VERSION "synthetic -- generated by libs/dbc_parser/tests/gen_golden.py"

NS_ :

BS_:

BU_ : ECU

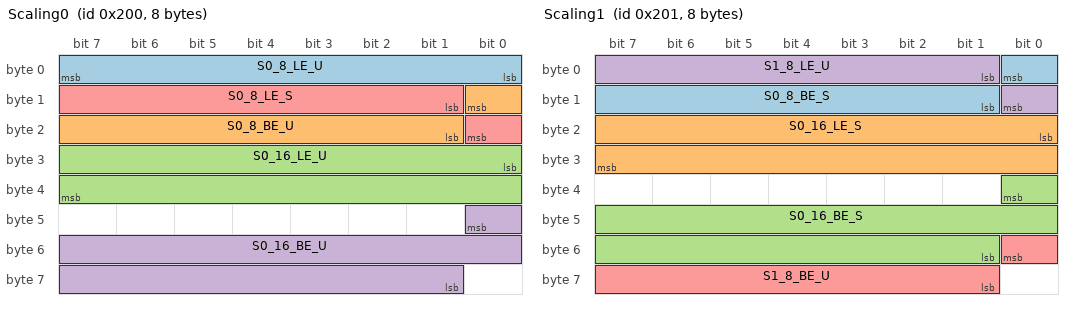
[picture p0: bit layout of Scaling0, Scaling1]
BO_ 512 Scaling0: 8 ECU
 SG_ S0_8_LE_U : 0|8@1+ (1,0) [0|255] "" ECU
 SG_ S0_8_BE_U : 8|8@0+ (1,0) [0|255] "" ECU
 SG_ S0_16_LE_U : 24|16@1+ (1,0) [0|65535] "" ECU
 SG_ S0_16_BE_U : 40|16@0+ (1,0) [0|65535] "" ECU
 SG_ S0_8_LE_S : 9|8@1- (1,0) [-128|127] "" ECU

BO_ 513 Scaling1: 8 ECU
 SG_ S0_8_BE_S : 0|8@0- (1,0) [-128|127] "" ECU
 SG_ S0_16_LE_S : 16|16@1- (1,0) [-32768|32767] "" ECU
 SG_ S0_16_BE_S : 32|16@0- (1,0) [-32768|32767] "" ECU
 SG_ S1_8_LE_U : 1|8@1+ (1,-40) [-40|215] "" ECU
 SG_ S1_8_BE_U : 48|8@0+ (1,-40) [-40|215] "" ECU

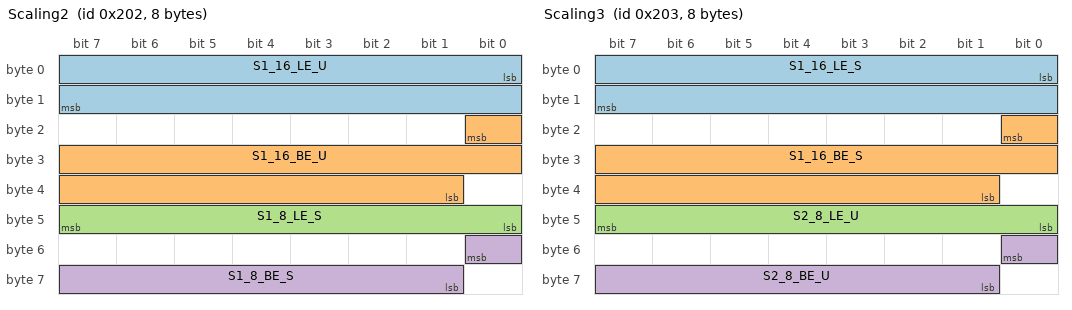
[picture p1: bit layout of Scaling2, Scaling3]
BO_ 514 Scaling2: 8 ECU
 SG_ S1_16_LE_U : 0|16@1+ (1,-40) [-40|65495] "" ECU
 SG_ S1_16_BE_U : 16|16@0+ (1,-40) [-40|65495] "" ECU
 SG_ S1_8_LE_S : 40|8@1- (1,-40) [-168|87] "" ECU
 SG_ S1_8_BE_S : 48|8@0- (1,-40) [-168|87] "" ECU

BO_ 515 Scaling3: 8 ECU
 SG_ S1_16_LE_S : 0|16@1- (1,-40) [-32808|32727] "" ECU
 SG_ S1_16_BE_S : 16|16@0- (1,-40) [-32808|32727] "" ECU
 SG_ S2_8_LE_U : 40|8@1+ (1,100) [100|355] "" ECU
 SG_ S2_8_BE_U : 48|8@0+ (1,100) [100|355] "" ECU

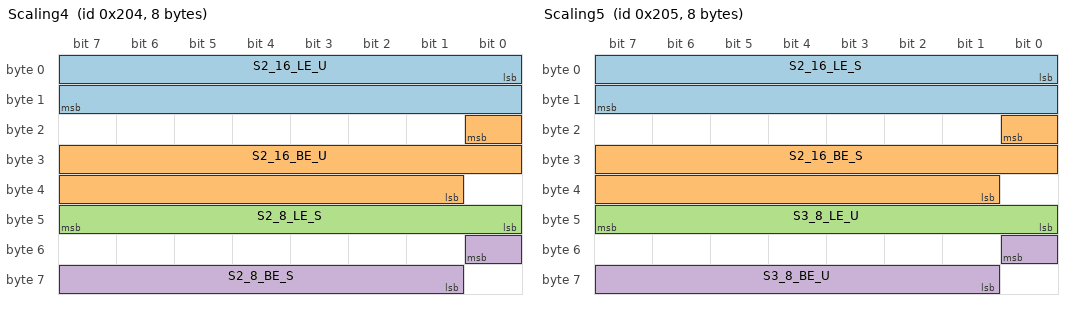
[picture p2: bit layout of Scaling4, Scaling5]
BO_ 516 Scaling4: 8 ECU
 SG_ S2_16_LE_U : 0|16@1+ (1,100) [100|65635] "" ECU
 SG_ S2_16_BE_U : 16|16@0+ (1,100) [100|65635] "" ECU
 SG_ S2_8_LE_S : 40|8@1- (1,100) [-28|227] "" ECU
 SG_ S2_8_BE_S : 48|8@0- (1,100) [-28|227] "" ECU

BO_ 517 Scaling5: 8 ECU
 SG_ S2_16_LE_S : 0|16@1- (1,100) [-32668|32867] "" ECU
 SG_ S2_16_BE_S : 16|16@0- (1,100) [-32668|32867] "" ECU
 SG_ S3_8_LE_U : 40|8@1+ (0.1,0) [0.0|25.5] "" ECU
 SG_ S3_8_BE_U : 48|8@0+ (0.1,0) [0.0|25.5] "" ECU

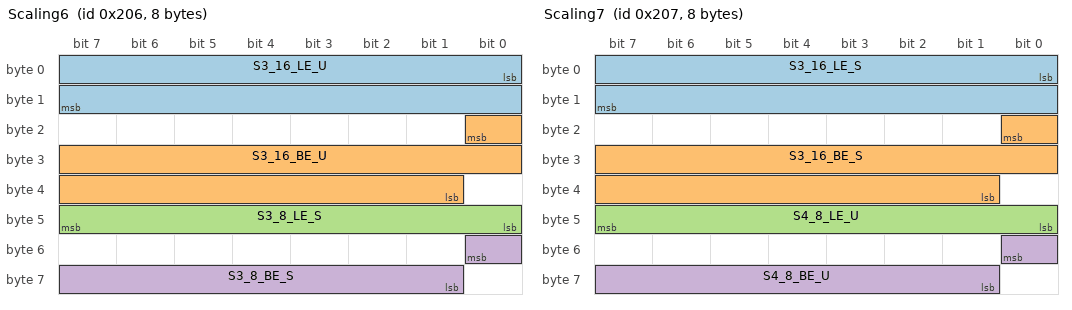
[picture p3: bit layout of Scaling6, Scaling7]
BO_ 518 Scaling6: 8 ECU
 SG_ S3_16_LE_U : 0|16@1+ (0.1,0) [0.0|6553.5] "" ECU
 SG_ S3_16_BE_U : 16|16@0+ (0.1,0) [0.0|6553.5] "" ECU
 SG_ S3_8_LE_S : 40|8@1- (0.1,0) [-12.8|12.700000000000001] "" ECU
 SG_ S3_8_BE_S : 48|8@0- (0.1,0) [-12.8|12.700000000000001] "" ECU

BO_ 519 Scaling7: 8 ECU
 SG_ S3_16_LE_S : 0|16@1- (0.1,0) [-3276.8|3276.7000000000003] "" ECU
 SG_ S3_16_BE_S : 16|16@0- (0.1,0) [-3276.8|3276.7000000000003] "" ECU
 SG_ S4_8_LE_U : 40|8@1+ (0.5,-273.15) [-273.15|-145.64999999999998] "" ECU
 SG_ S4_8_BE_U : 48|8@0+ (0.5,-273.15) [-273.15|-145.64999999999998] "" ECU

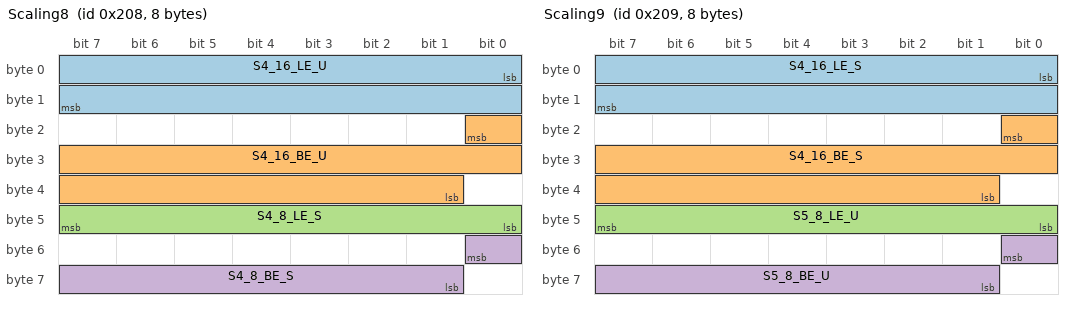
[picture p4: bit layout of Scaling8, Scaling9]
BO_ 520 Scaling8: 8 ECU
 SG_ S4_16_LE_U : 0|16@1+ (0.5,-273.15) [-273.15|32494.35] "" ECU
 SG_ S4_16_BE_U : 16|16@0+ (0.5,-273.15) [-273.15|32494.35] "" ECU
 SG_ S4_8_LE_S : 40|8@1- (0.5,-273.15) [-337.15|-209.64999999999998] "" ECU
 SG_ S4_8_BE_S : 48|8@0- (0.5,-273.15) [-337.15|-209.64999999999998] "" ECU

BO_ 521 Scaling9: 8 ECU
 SG_ S4_16_LE_S : 0|16@1- (0.5,-273.15) [-16657.15|16110.35] "" ECU
 SG_ S4_16_BE_S : 16|16@0- (0.5,-273.15) [-16657.15|16110.35] "" ECU
 SG_ S5_8_LE_U : 40|8@1+ (-1,0) [-255|0] "" ECU
 SG_ S5_8_BE_U : 48|8@0+ (-1,0) [-255|0] "" ECU

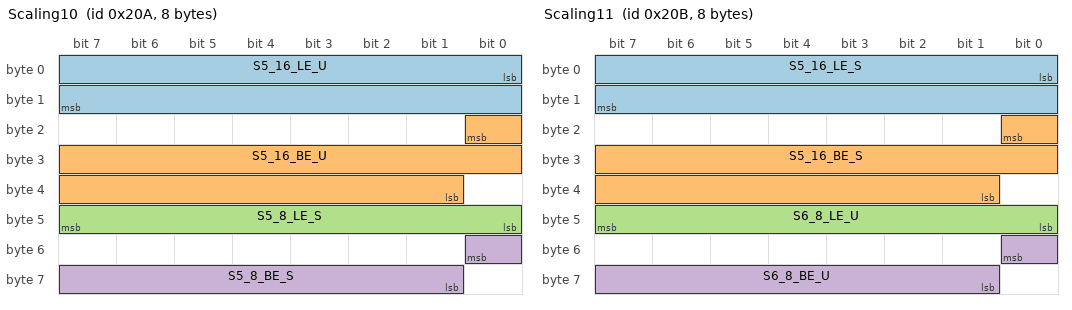
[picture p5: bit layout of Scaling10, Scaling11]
BO_ 522 Scaling10: 8 ECU
 SG_ S5_16_LE_U : 0|16@1+ (-1,0) [-65535|0] "" ECU
 SG_ S5_16_BE_U : 16|16@0+ (-1,0) [-65535|0] "" ECU
 SG_ S5_8_LE_S : 40|8@1- (-1,0) [-127|128] "" ECU
 SG_ S5_8_BE_S : 48|8@0- (-1,0) [-127|128] "" ECU

BO_ 523 Scaling11: 8 ECU
 SG_ S5_16_LE_S : 0|16@1- (-1,0) [-32767|32768] "" ECU
 SG_ S5_16_BE_S : 16|16@0- (-1,0) [-32767|32768] "" ECU
 SG_ S6_8_LE_U : 40|8@1+ (-0.25,10) [-53.75|10.0] "" ECU
 SG_ S6_8_BE_U : 48|8@0+ (-0.25,10) [-53.75|10.0] "" ECU

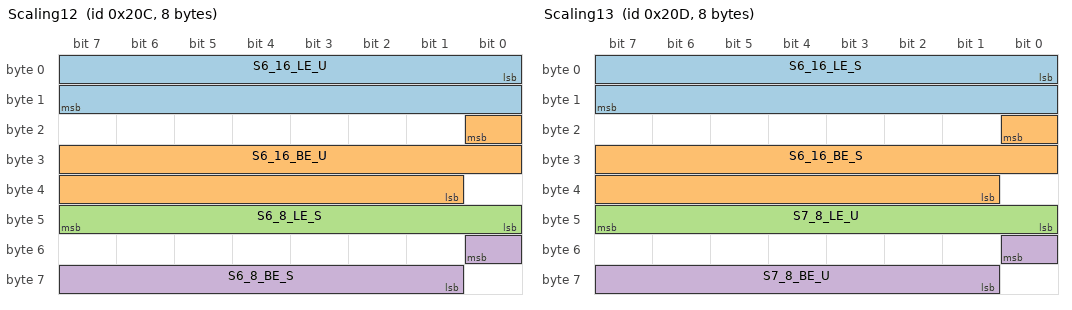
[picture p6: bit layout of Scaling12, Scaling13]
BO_ 524 Scaling12: 8 ECU
 SG_ S6_16_LE_U : 0|16@1+ (-0.25,10) [-16373.75|10.0] "" ECU
 SG_ S6_16_BE_U : 16|16@0+ (-0.25,10) [-16373.75|10.0] "" ECU
 SG_ S6_8_LE_S : 40|8@1- (-0.25,10) [-21.75|42.0] "" ECU
 SG_ S6_8_BE_S : 48|8@0- (-0.25,10) [-21.75|42.0] "" ECU

BO_ 525 Scaling13: 8 ECU
 SG_ S6_16_LE_S : 0|16@1- (-0.25,10) [-8181.75|8202.0] "" ECU
 SG_ S6_16_BE_S : 16|16@0- (-0.25,10) [-8181.75|8202.0] "" ECU
 SG_ S7_8_LE_U : 40|8@1+ (2,0) [0|510] "" ECU
 SG_ S7_8_BE_U : 48|8@0+ (2,0) [0|510] "" ECU

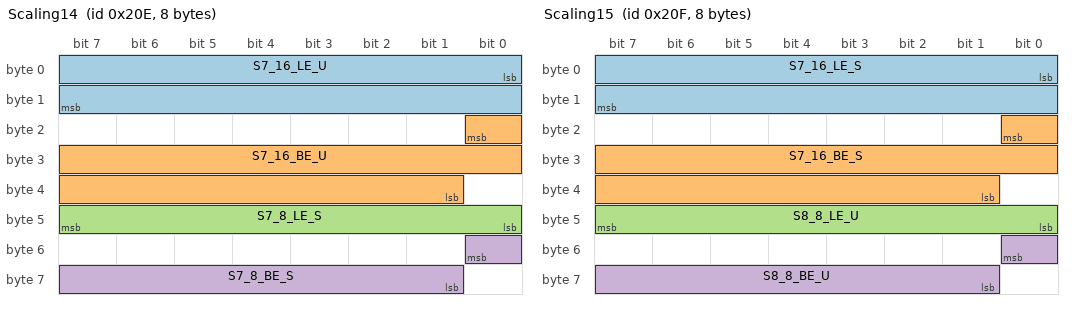
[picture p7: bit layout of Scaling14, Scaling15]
BO_ 526 Scaling14: 8 ECU
 SG_ S7_16_LE_U : 0|16@1+ (2,0) [0|131070] "" ECU
 SG_ S7_16_BE_U : 16|16@0+ (2,0) [0|131070] "" ECU
 SG_ S7_8_LE_S : 40|8@1- (2,0) [-256|254] "" ECU
 SG_ S7_8_BE_S : 48|8@0- (2,0) [-256|254] "" ECU

BO_ 527 Scaling15: 8 ECU
 SG_ S7_16_LE_S : 0|16@1- (2,0) [-65536|65534] "" ECU
 SG_ S7_16_BE_S : 16|16@0- (2,0) [-65536|65534] "" ECU
 SG_ S8_8_LE_U : 40|8@1+ (0.001,0) [0.0|0.255] "" ECU
 SG_ S8_8_BE_U : 48|8@0+ (0.001,0) [0.0|0.255] "" ECU

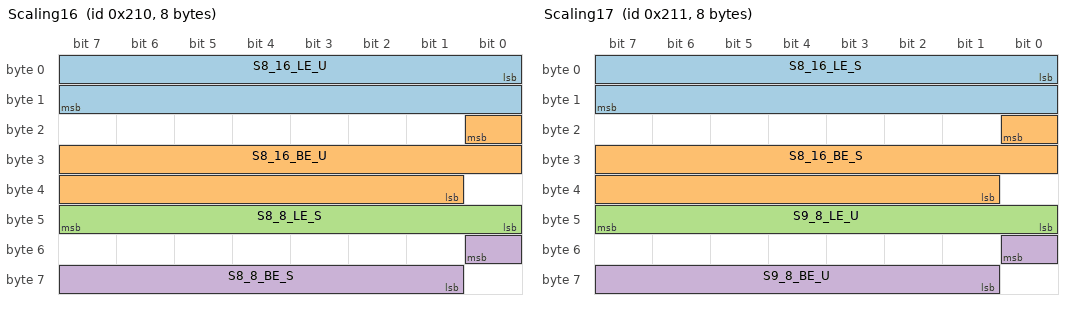
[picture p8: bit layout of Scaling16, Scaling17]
BO_ 528 Scaling16: 8 ECU
 SG_ S8_16_LE_U : 0|16@1+ (0.001,0) [0.0|65.535] "" ECU
 SG_ S8_16_BE_U : 16|16@0+ (0.001,0) [0.0|65.535] "" ECU
 SG_ S8_8_LE_S : 40|8@1- (0.001,0) [-0.128|0.127] "" ECU
 SG_ S8_8_BE_S : 48|8@0- (0.001,0) [-0.128|0.127] "" ECU

BO_ 529 Scaling17: 8 ECU
 SG_ S8_16_LE_S : 0|16@1- (0.001,0) [-32.768|32.767] "" ECU
 SG_ S8_16_BE_S : 16|16@0- (0.001,0) [-32.768|32.767] "" ECU
 SG_ S9_8_LE_U : 40|8@1+ (1000,0) [0|255000] "" ECU
 SG_ S9_8_BE_U : 48|8@0+ (1000,0) [0|255000] "" ECU

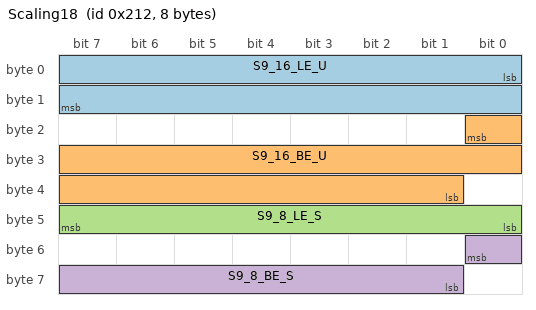
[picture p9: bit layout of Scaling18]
BO_ 530 Scaling18: 8 ECU
 SG_ S9_16_LE_U : 0|16@1+ (1000,0) [0|65535000] "" ECU
 SG_ S9_16_BE_U : 16|16@0+ (1000,0) [0|65535000] "" ECU
 SG_ S9_8_LE_S : 40|8@1- (1000,0) [-128000|127000] "" ECU
 SG_ S9_8_BE_S : 48|8@0- (1000,0) [-128000|127000] "" ECU

BO_ 531 Scaling19: 8 ECU
 SG_ S9_16_LE_S : 0|16@1- (1000,0) [-32768000|32767000] "" ECU
 SG_ S9_16_BE_S : 16|16@0- (1000,0) [-32768000|32767000] "" ECU
